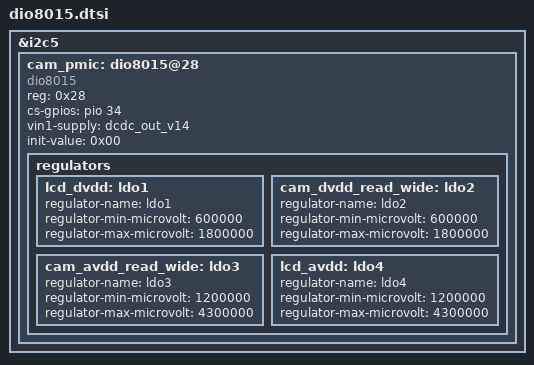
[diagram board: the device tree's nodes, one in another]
/*dio8015 dtsi*/

&i2c5 {
	status = "ok";
	cam_pmic: dio8015@28 {
		compatible = "dio8015";
		reg = <0x28>;

		cs-gpios = <&pio 34 0>;
		vin1-supply = <&dcdc_out_v14>;

		init-value = <0x00>;

		regulators {
			lcd_dvdd: ldo1 {
				regulator-name = "ldo1";
				regulator-min-microvolt = <600000>;
				regulator-max-microvolt = <1800000>;
			};

			cam_dvdd_read_wide: ldo2 {
				regulator-name = "ldo2";
				regulator-min-microvolt = <600000>;
				regulator-max-microvolt = <1800000>;
			};

			cam_avdd_read_wide: ldo3 {
				regulator-name = "ldo3";
				regulator-min-microvolt = <1200000>;
				regulator-max-microvolt = <4300000>;
			};

			lcd_avdd: ldo4 {
				regulator-name = "ldo4";
				regulator-min-microvolt = <1200000>;
				regulator-max-microvolt = <4300000>;
			};
		};
	};
};
